VERSION ""

NS_ :

BS_ :

BU_ : ADAS BDY CAM EBCM EON EPS PCM SCM VSA XXX

BO_ 57 UNKNOWN_039: 2 XXX

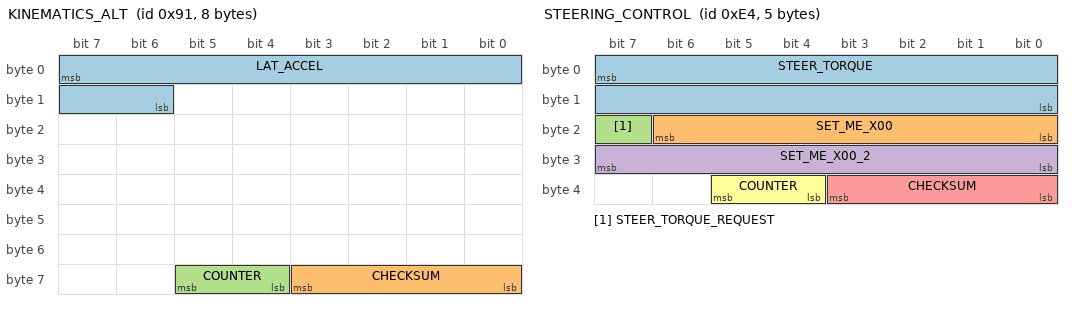
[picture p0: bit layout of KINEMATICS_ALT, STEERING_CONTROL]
BO_ 145 KINEMATICS_ALT: 8 XXX
 SG_ LAT_ACCEL : 7|10@0+ (0.02,-512) [-20|20] "m/s2" EON
 SG_ CHECKSUM : 59|4@0+ (1,0) [0|3] "" EON
 SG_ COUNTER : 61|2@0+ (1,0) [0|3] "" EON

BO_ 228 STEERING_CONTROL: 5 ADAS
 SG_ STEER_TORQUE : 7|16@0- (1,0) [-3840|3840] "" EPS
 SG_ SET_ME_X00 : 22|7@0+ (1,0) [0|127] "" EPS
 SG_ STEER_TORQUE_REQUEST : 23|1@0+ (1,0) [0|1] "" EPS
 SG_ SET_ME_X00_2 : 31|8@0+ (1,0) [0|0] "" EPS
 SG_ CHECKSUM : 35|4@0+ (1,0) [0|15] "" EPS
 SG_ COUNTER : 37|2@0+ (1,0) [0|3] "" EPS

BO_ 310 NEW_MSG_136: 8 XXX

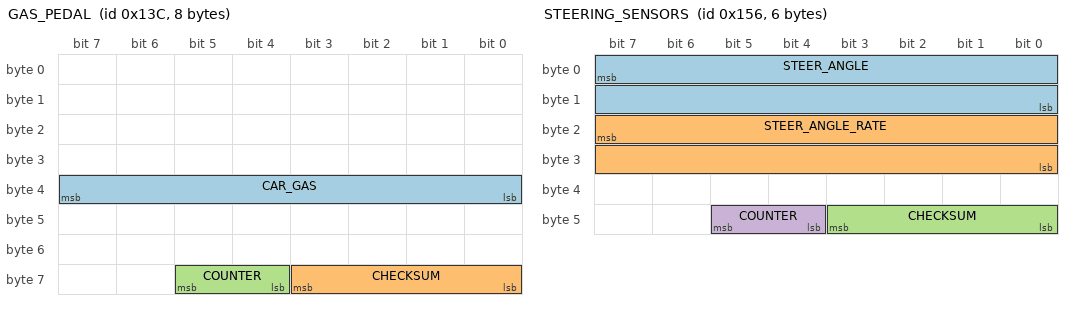
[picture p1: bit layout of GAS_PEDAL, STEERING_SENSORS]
BO_ 316 GAS_PEDAL: 8 PCM
 SG_ CAR_GAS : 39|8@0+ (1,0) [0|255] "" EON
 SG_ CHECKSUM : 59|4@0+ (1,0) [0|15] "" EON
 SG_ COUNTER : 61|2@0+ (1,0) [0|3] "" EON

BO_ 342 STEERING_SENSORS: 6 EPS
 SG_ STEER_ANGLE : 7|16@0- (-0.1,0) [-500|500] "deg" EON
 SG_ STEER_ANGLE_RATE : 23|16@0- (1,0) [-3000|3000] "deg/s" EON
 SG_ CHECKSUM : 43|4@0+ (1,0) [0|15] "" EON
 SG_ COUNTER : 45|2@0+ (1,0) [0|3] "" EON

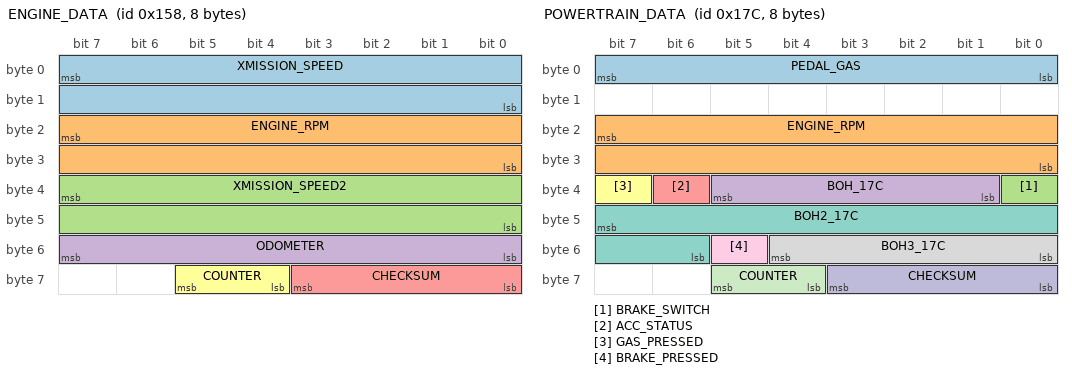
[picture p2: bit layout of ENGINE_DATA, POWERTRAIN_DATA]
BO_ 344 ENGINE_DATA: 8 PCM
 SG_ XMISSION_SPEED : 7|16@0+ (0.01,0) [0|250] "kph" EON
 SG_ ENGINE_RPM : 23|16@0+ (1,0) [0|15000] "rpm" EON
 SG_ XMISSION_SPEED2 : 39|16@0+ (0.01,0) [0|250] "kph" EON
 SG_ ODOMETER : 55|8@0+ (10,0) [0|2550] "m" XXX
 SG_ CHECKSUM : 59|4@0+ (1,0) [0|15] "" EON
 SG_ COUNTER : 61|2@0+ (1,0) [0|3] "" EON

BO_ 380 POWERTRAIN_DATA: 8 PCM
 SG_ PEDAL_GAS : 7|8@0+ (1,0) [0|255] "" EON
 SG_ ENGINE_RPM : 23|16@0+ (1,0) [0|15000] "rpm" EON
 SG_ BRAKE_SWITCH : 32|1@0+ (1,0) [0|1] "" EON
 SG_ BOH_17C : 37|5@0+ (1,0) [0|1] "" EON
 SG_ ACC_STATUS : 38|1@0+ (1,0) [0|1] "" EON
 SG_ GAS_PRESSED : 39|1@0+ (1,0) [0|1] "" EON
 SG_ BOH2_17C : 47|10@0+ (1,0) [0|1] "" EON
 SG_ BOH3_17C : 52|5@0+ (1,0) [0|1] "" EON
 SG_ BRAKE_PRESSED : 53|1@0+ (1,0) [0|1] "" EON
 SG_ CHECKSUM : 59|4@0+ (1,0) [0|15] "" EON
 SG_ COUNTER : 61|2@0+ (1,0) [0|3] "" EON

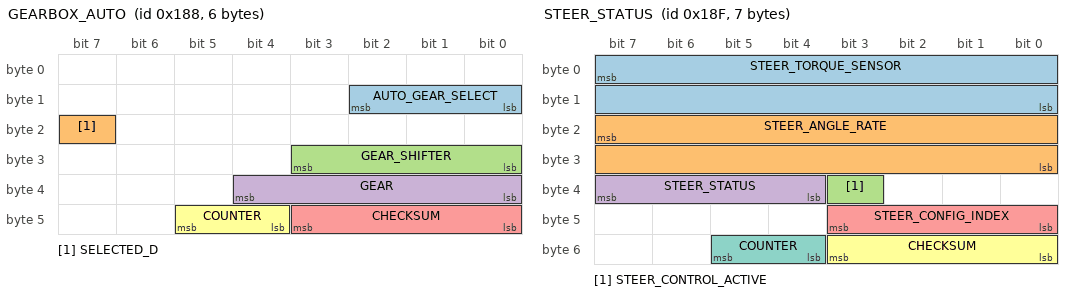
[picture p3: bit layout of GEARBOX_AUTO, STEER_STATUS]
BO_ 392 GEARBOX_AUTO: 6 XXX
 SG_ AUTO_GEAR_SELECT : 10|3@0+ (1,0) [0|7] "" XXX
 SG_ SELECTED_D : 23|1@0+ (1,0) [0|1] "" XXX
 SG_ GEAR_SHIFTER : 27|4@0+ (1,0) [0|15] "" EON
 SG_ GEAR : 36|5@0+ (1,0) [0|31] "" EON
 SG_ CHECKSUM : 43|4@0+ (1,0) [0|15] "" XXX
 SG_ COUNTER : 45|2@0+ (1,0) [0|3] "" XXX

BO_ 398 UNKNOWN_18E: 3 XXX

BO_ 399 STEER_STATUS: 7 EPS
 SG_ STEER_TORQUE_SENSOR : 7|16@0- (-1,0) [-31000|31000] "tbd" EON
 SG_ STEER_ANGLE_RATE : 23|16@0- (-0.1,0) [-31000|31000] "deg/s" EON
 SG_ STEER_CONTROL_ACTIVE : 35|1@0+ (1,0) [0|1] "" EON
 SG_ STEER_STATUS : 39|4@0+ (1,0) [0|15] "" EON
 SG_ STEER_CONFIG_INDEX : 43|4@0+ (1,0) [0|15] "" EON
 SG_ CHECKSUM : 51|4@0+ (1,0) [0|3] "" EON
 SG_ COUNTER : 53|2@0+ (1,0) [0|3] "" EON

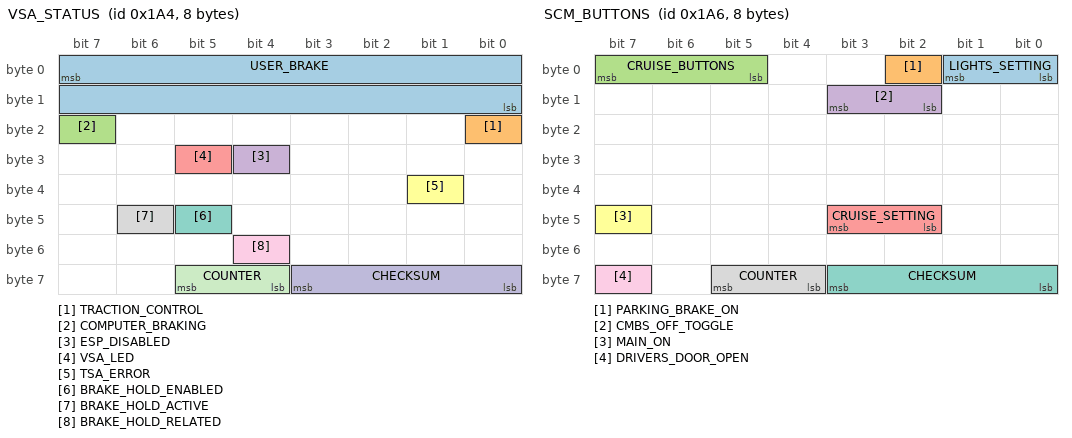
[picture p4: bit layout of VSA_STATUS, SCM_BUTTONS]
BO_ 420 VSA_STATUS: 8 VSA
 SG_ USER_BRAKE : 7|16@0+ (0.015625,-1.609375) [0|1000] "" EON
 SG_ TRACTION_CONTROL : 16|1@0+ (1,0) [0|1] "" XXX
 SG_ COMPUTER_BRAKING : 23|1@0+ (1,0) [0|1] "" EON
 SG_ ESP_DISABLED : 28|1@0+ (1,0) [0|1] "" EON
 SG_ VSA_LED : 29|1@0+ (1,0) [0|1] "" XXX
 SG_ TSA_ERROR : 33|1@0+ (1,0) [0|1] "" XXX
 SG_ BRAKE_HOLD_ENABLED : 45|1@0+ (1,0) [0|1] "" EON
 SG_ BRAKE_HOLD_ACTIVE : 46|1@0+ (1,0) [0|1] "" EON
 SG_ BRAKE_HOLD_RELATED : 52|1@0+ (1,0) [0|1] "" XXX
 SG_ CHECKSUM : 59|4@0+ (1,0) [0|15] "" EON
 SG_ COUNTER : 61|2@0+ (1,0) [0|3] "" EON

BO_ 422 SCM_BUTTONS: 8 SCM
 SG_ LIGHTS_SETTING : 1|2@0+ (1,0) [0|3] "" EON
 SG_ PARKING_BRAKE_ON : 2|1@0+ (1,0) [0|1] "" EON
 SG_ CRUISE_BUTTONS : 7|3@0+ (1,0) [0|7] "" EON
 SG_ CMBS_OFF_TOGGLE : 11|2@0+ (1,0) [0|3] "" EON
 SG_ CRUISE_SETTING : 43|2@0+ (1,0) [0|3] "" EON
 SG_ MAIN_ON : 47|1@0+ (1,0) [0|1] "" EON
 SG_ CHECKSUM : 59|4@0+ (1,0) [0|15] "" EON
 SG_ COUNTER : 61|2@0+ (1,0) [0|3] "" EON
 SG_ DRIVERS_DOOR_OPEN : 63|1@0+ (1,0) [0|1] "" EON

BO_ 426 UNKNOWN_1AA: 8 XXX

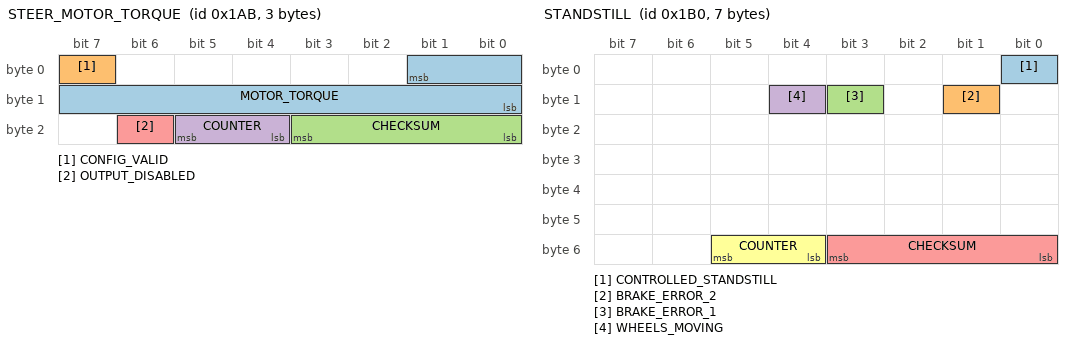
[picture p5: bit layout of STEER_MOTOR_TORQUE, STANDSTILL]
BO_ 427 STEER_MOTOR_TORQUE: 3 EPS
 SG_ MOTOR_TORQUE : 1|10@0+ (1,0) [0|256] "" EON
 SG_ CONFIG_VALID : 7|1@0+ (1,0) [0|1] "" EON
 SG_ CHECKSUM : 19|4@0+ (1,0) [0|15] "" EON
 SG_ COUNTER : 21|2@0+ (1,0) [0|3] "" EON
 SG_ OUTPUT_DISABLED : 22|1@0+ (1,0) [0|1] "" EON

BO_ 432 STANDSTILL: 7 VSA
 SG_ CONTROLLED_STANDSTILL : 0|1@0+ (1,0) [0|1] "" EON
 SG_ BRAKE_ERROR_2 : 9|1@0+ (1,0) [0|1] "" EON
 SG_ BRAKE_ERROR_1 : 11|1@0+ (1,0) [0|1] "" EON
 SG_ WHEELS_MOVING : 12|1@0+ (1,0) [0|1] "" EON
 SG_ CHECKSUM : 51|4@0+ (1,0) [0|3] "" EON
 SG_ COUNTER : 53|2@0+ (1,0) [0|3] "" EON

BO_ 448 BRAKE_COMMAND: 7 XXX
 SG_ COMPUTER_BRAKE : 7|10@0+ (1,0) [0|1] "" EBCM
 SG_ BRAKE_PUMP_REQUEST : 8|1@0+ (1,0) [0|1] "" EBCM
 SG_ BRAKE_PUMP_REQUEST_HYBRID : 11|1@0+ (1,0) [0|1] "" EBCM
 SG_ CMBS_DISABLED : 12|1@0+ (1,0) [0|1] "" XXX
 SG_ COMPUTER_BRAKE_REQUEST : 16|1@0+ (1,0) [0|1] "" EBCM
 SG_ CRUISE_CANCEL_CMD : 17|1@0+ (1,0) [0|1] "" EBCM
 SG_ CRUISE_FAULT_CMD : 18|1@0+ (1,0) [0|1] "" EBCM
 SG_ SET_ME_X00_2 : 19|1@0+ (1,0) [0|1] "" EBCM
 SG_ CRUISE_OVERRIDE : 20|1@0+ (1,0) [0|1] "" EBCM
 SG_ ACC_OVERRIDE_STOP : 21|1@0+ (1,0) [0|1] "" EBCM
 SG_ SET_ME_0 : 22|1@0+ (1,0) [0|1] "" EBCM
 SG_ ACC_LAST_BIT : 23|1@0+ (1,0) [0|1] "" EBCM
 SG_ AEB_REQ_2 : 26|3@0+ (1,0) [0|7] "" XXX
 SG_ AEB_REQ_1 : 29|2@0+ (1,0) [0|1] "" XXX
 SG_ IMPERIAL_UNIT : 31|1@0+ (1,0) [0|1] "" EBCM
 SG_ CRUISE_STATES : 38|7@0+ (1,0) [0|1] "" EBCM
 SG_ BRAKE_LIGHTS : 39|1@0+ (1,0) [0|1] "" EBCM
 SG_ AEB_STATUS : 41|2@0+ (1,0) [0|3] "" XXX
 SG_ FCW : 43|2@0+ (1,0) [0|3] "" EBCM
 SG_ SET_ME_X00_3 : 44|1@0+ (1,0) [0|1] "" EBCM
 SG_ CHIME : 47|3@0+ (1,0) [0|7] "" EBCM
 SG_ CHECKSUM : 51|4@0+ (1,0) [0|15] "" EBCM
 SG_ COUNTER : 53|2@0+ (1,0) [0|3] "" EBCM

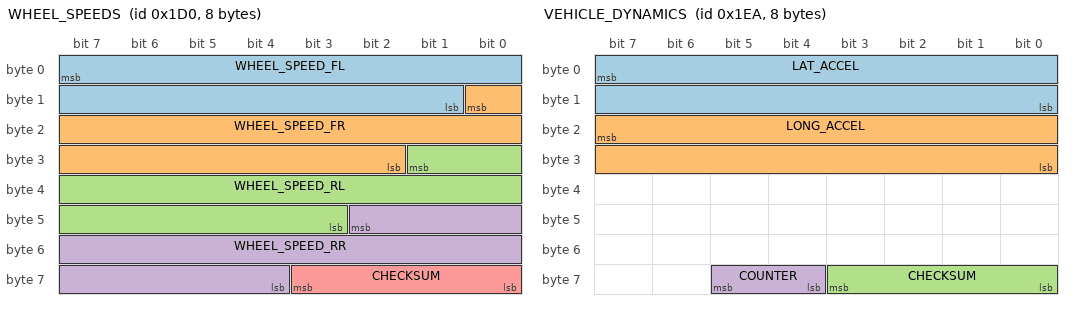
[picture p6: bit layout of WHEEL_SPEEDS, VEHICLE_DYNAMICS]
BO_ 464 WHEEL_SPEEDS: 8 VSA
 SG_ WHEEL_SPEED_FL : 7|15@0+ (0.01,0) [0|250] "kph" EON
 SG_ WHEEL_SPEED_FR : 8|15@0+ (0.01,0) [0|250] "kph" EON
 SG_ WHEEL_SPEED_RL : 25|15@0+ (0.01,0) [0|250] "kph" EON
 SG_ WHEEL_SPEED_RR : 42|15@0+ (0.01,0) [0|250] "kph" EON
 SG_ CHECKSUM : 59|4@0+ (1,0) [0|3] "" EON

BO_ 476 UNKNOWN_1DC: 4 XXX

BO_ 490 VEHICLE_DYNAMICS: 8 VSA
 SG_ LAT_ACCEL : 7|16@0- (0.0015,0) [-20|20] "m/s2" EON
 SG_ LONG_ACCEL : 23|16@0- (0.0015,0) [-20|20] "m/s2" EON
 SG_ CHECKSUM : 59|4@0+ (1,0) [0|3] "" EON
 SG_ COUNTER : 61|2@0+ (1,0) [0|3] "" EON

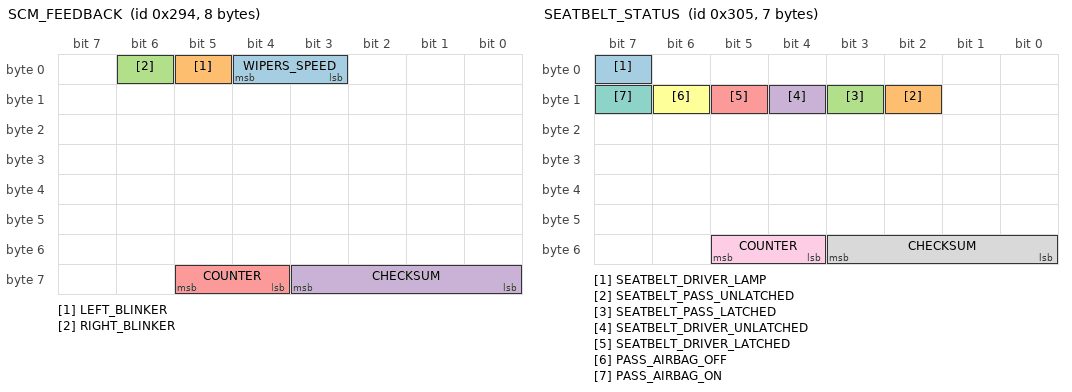
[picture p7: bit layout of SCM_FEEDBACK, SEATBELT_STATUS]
BO_ 660 SCM_FEEDBACK: 8 SCM
 SG_ WIPERS_SPEED : 4|2@0+ (1,0) [0|3] "" EON
 SG_ LEFT_BLINKER : 5|1@0+ (1,0) [0|1] "" EON
 SG_ RIGHT_BLINKER : 6|1@0+ (1,0) [0|1] "" EON
 SG_ CHECKSUM : 59|4@0+ (1,0) [0|15] "" EON
 SG_ COUNTER : 61|2@0+ (1,0) [0|3] "" EON

BO_ 773 SEATBELT_STATUS: 7 BDY
 SG_ SEATBELT_DRIVER_LAMP : 7|1@0+ (1,0) [0|1] "" EON
 SG_ SEATBELT_PASS_UNLATCHED : 10|1@0+ (1,0) [0|1] "" EON
 SG_ SEATBELT_PASS_LATCHED : 11|1@0+ (1,0) [0|1] "" EON
 SG_ SEATBELT_DRIVER_UNLATCHED : 12|1@0+ (1,0) [0|1] "" EON
 SG_ SEATBELT_DRIVER_LATCHED : 13|1@0+ (1,0) [0|1] "" EON
 SG_ PASS_AIRBAG_OFF : 14|1@0+ (1,0) [0|1] "" EON
 SG_ PASS_AIRBAG_ON : 15|1@0+ (1,0) [0|1] "" EON
 SG_ CHECKSUM : 51|4@0+ (1,0) [0|3] "" EON
 SG_ COUNTER : 53|2@0+ (1,0) [0|3] "" EON

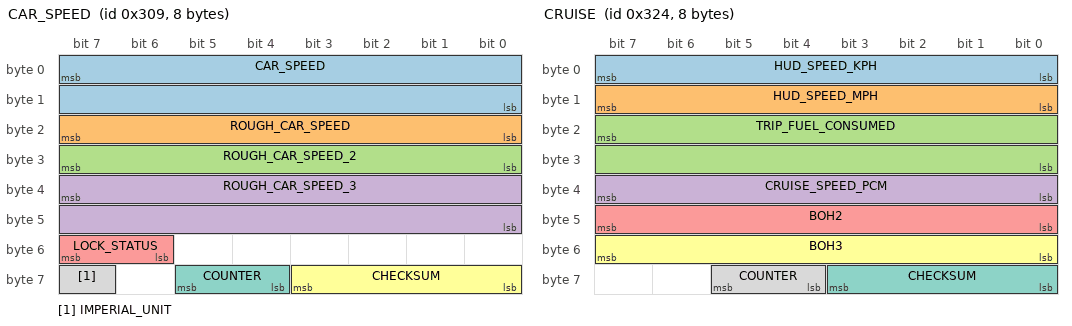
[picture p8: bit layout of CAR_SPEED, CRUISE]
BO_ 777 CAR_SPEED: 8 PCM
 SG_ CAR_SPEED : 7|16@0+ (0.01,0) [0|65535] "kph" XXX
 SG_ ROUGH_CAR_SPEED : 23|8@0+ (1,0) [0|255] "mph" XXX
 SG_ ROUGH_CAR_SPEED_2 : 31|8@0+ (1,0) [0|255] "mph" XXX
 SG_ ROUGH_CAR_SPEED_3 : 39|16@0+ (1,0) [0|65535] "kph" XXX
 SG_ LOCK_STATUS : 55|2@0+ (1,0) [0|255] "" XXX
 SG_ CHECKSUM : 59|4@0+ (1,0) [0|15] "" XXX
 SG_ COUNTER : 61|2@0+ (1,0) [0|3] "" XXX
 SG_ IMPERIAL_UNIT : 63|1@0+ (1,0) [0|1] "" XXX

BO_ 780 ACC_HUD: 8 ADAS
 SG_ PCM_SPEED : 7|16@0+ (0.01,0) [0|655.35] "kph" BDY
 SG_ PCM_GAS : 23|8@0+ (1,0) [0|255] "" BDY
 SG_ CRUISE_SPEED : 31|8@0+ (1,0) [0|255] "kph" BDY
 SG_ ENABLE_MINI_CAR : 32|1@0+ (1,0) [0|1] "" BDY
 SG_ RADAR_OBSTRUCTED : 33|1@0+ (1,0) [0|1] "" BDY
 SG_ FCM_PROBLEM : 34|1@0+ (1,0) [0|1] "" BDY
 SG_ FCM_OFF : 35|1@0+ (1,0) [0|1] "" BDY
 SG_ FCM_OFF_2 : 36|1@0+ (1,0) [0|1] "" BDY
 SG_ ACC_PROBLEM : 37|1@0+ (1,0) [0|1] "" BDY
 SG_ BRAKE_SYSTEM_ICON : 38|1@0+ (1,0) [0|1] "" BDY
 SG_ DTC_MODE : 39|1@0+ (1,0) [0|1] "" BDY
 SG_ CRUISE_CONTROL_LABEL : 40|1@0+ (1,0) [0|1] "" BDY
 SG_ BOH_5 : 41|1@0+ (1,0) [0|1] "" BDY
 SG_ BOH_4 : 42|1@0+ (1,0) [0|1] "" BDY
 SG_ BOH_3 : 43|1@0+ (1,0) [0|1] "" BDY
 SG_ HUD_LEAD : 45|2@0+ (1,0) [0|3] "" BDY
 SG_ HUD_DISTANCE : 47|2@0+ (1,0) [0|3] "" BDY
 SG_ ACC_HUD_STROBE : 48|1@0+ (1,0) [0|1] "" BDY
 SG_ CHIME : 51|3@0+ (1,0) [0|7] "" BDY
 SG_ ACC_ON : 52|1@0+ (1,0) [0|1] "" BDY
 SG_ IMPERIAL_UNIT : 54|1@0+ (1,0) [0|1] "" BDY
 SG_ SET_ME_X01_2 : 55|1@0+ (1,0) [0|1] "" BDY
 SG_ CHECKSUM : 59|4@0+ (1,0) [0|15] "" BDY
 SG_ COUNTER : 61|2@0+ (1,0) [0|3] "" BDY
 SG_ ICONS : 63|2@0+ (1,0) [0|3] "" BDY

BO_ 800 UNKNOWN_320: 3 XXX

BO_ 804 CRUISE: 8 PCM
 SG_ HUD_SPEED_KPH : 7|8@0+ (1,0) [0|255] "kph" EON
 SG_ HUD_SPEED_MPH : 15|8@0+ (1,0) [0|255] "mph" EON
 SG_ TRIP_FUEL_CONSUMED : 23|16@0+ (1,0) [0|255] "" EON
 SG_ CRUISE_SPEED_PCM : 39|8@0+ (1,0) [0|255] "" EON
 SG_ BOH2 : 47|8@0- (1,0) [0|255] "" EON
 SG_ BOH3 : 55|8@0+ (1,0) [0|255] "" EON
 SG_ CHECKSUM : 59|4@0+ (1,0) [0|15] "" EON
 SG_ COUNTER : 61|2@0+ (1,0) [0|3] "" EON

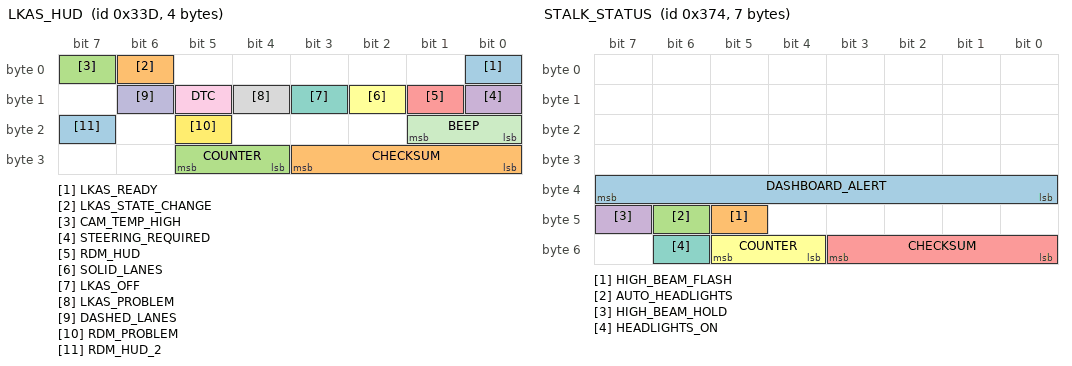
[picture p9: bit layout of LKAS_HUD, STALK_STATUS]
BO_ 829 LKAS_HUD: 4 ADAS
 SG_ LKAS_READY : 0|1@0+ (1,0) [0|127] "" BDY
 SG_ LKAS_STATE_CHANGE : 6|1@0+ (1,0) [0|1] "" XXX
 SG_ CAM_TEMP_HIGH : 7|1@0+ (1,0) [0|255] "" BDY
 SG_ STEERING_REQUIRED : 8|1@0+ (1,0) [0|1] "" BDY
 SG_ RDM_HUD : 9|1@0+ (1,0) [0|1] "" BDY
 SG_ SOLID_LANES : 10|1@0+ (1,0) [0|1] "" BDY
 SG_ LKAS_OFF : 11|1@0+ (1,0) [0|1] "" BDY
 SG_ LKAS_PROBLEM : 12|1@0+ (1,0) [0|1] "" BDY
 SG_ DTC : 13|1@0+ (1,0) [0|1] "" BDY
 SG_ DASHED_LANES : 14|1@0+ (1,0) [0|1] "" BDY
 SG_ BEEP : 17|2@0+ (1,0) [0|1] "" BDY
 SG_ RDM_PROBLEM : 21|1@0+ (1,0) [0|1] "" BDY
 SG_ RDM_HUD_2 : 23|1@0+ (1,0) [0|1] "" XXX
 SG_ CHECKSUM : 27|4@0+ (1,0) [0|15] "" BDY
 SG_ COUNTER : 29|2@0+ (1,0) [0|3] "" BDY

BO_ 884 STALK_STATUS: 7 XXX
 SG_ DASHBOARD_ALERT : 39|8@0+ (1,0) [0|255] "" EON
 SG_ HIGH_BEAM_FLASH : 45|1@0+ (1,0) [0|1] "" EON
 SG_ AUTO_HEADLIGHTS : 46|1@0+ (1,0) [0|1] "" EON
 SG_ HIGH_BEAM_HOLD : 47|1@0+ (1,0) [0|1] "" EON
 SG_ CHECKSUM : 51|4@0+ (1,0) [0|3] "" EON
 SG_ COUNTER : 53|2@0+ (1,0) [0|3] "" EON
 SG_ HEADLIGHTS_ON : 54|1@0+ (1,0) [0|1] "" EON

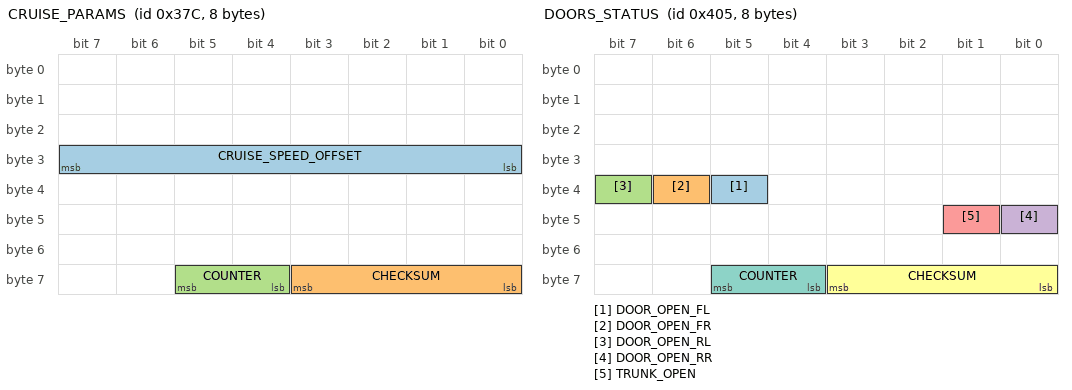
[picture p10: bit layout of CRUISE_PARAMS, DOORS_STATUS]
BO_ 892 CRUISE_PARAMS: 8 PCM
 SG_ CRUISE_SPEED_OFFSET : 31|8@0- (0.1,0) [-128|127] "kph" EON
 SG_ CHECKSUM : 59|4@0+ (1,0) [0|3] "" EON
 SG_ COUNTER : 61|2@0+ (1,0) [0|3] "" EON

BO_ 983 UNKNOWN_3D7: 8 XXX

BO_ 1024 UNKNOWN_400: 5 XXX

BO_ 1029 DOORS_STATUS: 8 BDY
 SG_ DOOR_OPEN_FL : 37|1@0+ (1,0) [0|1] "" EON
 SG_ DOOR_OPEN_FR : 38|1@0+ (1,0) [0|1] "" EON
 SG_ DOOR_OPEN_RL : 39|1@0+ (1,0) [0|1] "" EON
 SG_ DOOR_OPEN_RR : 40|1@0+ (1,0) [0|1] "" EON
 SG_ TRUNK_OPEN : 41|1@0+ (1,0) [0|1] "" EON
 SG_ CHECKSUM : 59|4@0+ (1,0) [0|15] "" EON
 SG_ COUNTER : 61|2@0+ (1,0) [0|3] "" EON

BO_ 1030 UNKNOWN_406: 5 XXX

BO_ 1036 UNKNOWN_40C: 8 XXX

BO_ 1064 UNKNOWN_428: 7 XXX

BO_ 1108 UNKNOWN_454: 6 XXX

BO_ 1125 UNKNOWN_465: 7 XXX

CM_ BO_ 57 "GUESS/unidentified: dlc 3 varying bytes [1, 2]; likely body/comfort/diagnostic.";
CM_ BO_ 228 "v3 note: OP steering TX (not on sampled non-lateral drives)";
CM_ SG_ 316 CAR_GAS "Should exist on Nidec";
CM_ BO_ 398 "GUESS/unidentified: dlc 3 varying bytes [1, 2]; likely body/comfort/diagnostic.";
CM_ SG_ 420 BRAKE_HOLD_RELATED "On when Brake Hold engaged";
CM_ BO_ 426 "GUESS/unidentified: dlc 8 varying bytes [3, 7]; likely body/comfort/diagnostic.";
CM_ BO_ 427 "v3 note: not seen on sample, verify";
CM_ BO_ 476 "GUESS: best match vEgo_kph corr 0.58; scale is a fit, verify.";
CM_ SG_ 490 LONG_ACCEL "wheel speed derivative, noisy and zero snapping";
CM_ SG_ 773 PASS_AIRBAG_OFF "Might just be indicator light";
CM_ SG_ 773 PASS_AIRBAG_ON "Might just be indicator light";
CM_ BO_ 780 "ACC_HUD, 10Hz, from radar/ACC unit. Same Honda checksum/counter as 506 (verified 100.0000% on 64880 stock frames). Stock never sets ACC_PROBLEM/FCM_*; those appear only when openpilot is active (7.2% duty on 84-8b).";
CM_ SG_ 780 PCM_SPEED "ACC target speed, 0.01 kph. =0 at standstill (84% of zero-speed frames). v3 max [0|250] was wrong (16-bit*0.01 -> 655.35).";
CM_ SG_ 780 PCM_GAS "ACC powertrain gas/torque request. Dominant idle value ~198; varies with ACC accel demand. v3 max [0|127] wrong (8-bit -> 255).";
CM_ SG_ 780 CRUISE_SPEED "Set speed in kph; 255 = no set speed (ACC not engaged). 255 in 53% of stock frames.";
CM_ SG_ 780 ENABLE_MINI_CAR "= ACC engaged. P(set|cruiseState.enabled)=1.00, P(set|!enabled)=0.001. Shows host car on HUD.";
CM_ SG_ 780 RADAR_OBSTRUCTED "0 in stock.";
CM_ SG_ 780 FCM_PROBLEM "Forward Camera/Radar Module problem. Tracks ACC_PROBLEM. 0 in stock, 7.2% when OP active.";
CM_ SG_ 780 FCM_OFF "0 in stock.";
CM_ SG_ 780 FCM_OFF_2 "0 in stock.";
CM_ SG_ 780 ACC_PROBLEM "ACC fault annunciation. Stock 81/82: 0. OP-active 84-8b: 1 in 7.21% (3507 onsets). Equals FCM_PROBLEM (99.996%). Primary bit behind the dash ACC error.";
CM_ SG_ 780 BRAKE_SYSTEM_ICON "Rare (106/64880); pairs with ICONS=3.";
CM_ SG_ 780 CRUISE_CONTROL_LABEL "0 in stock (1-bit; v3 max [0|3] corrected to [0|1]).";
CM_ SG_ 780 BOH_5 "0 in stock.";
CM_ SG_ 780 BOH_3 "0 in stock.";
CM_ SG_ 780 HUD_LEAD "0=ACC off / no host car; 1=engaged, no lead; 2=engaged, lead shown; 3=lead while disengaged (warning). Joint with ENABLE_MINI_CAR: =0 when mini_car=0, =1/2 split by lead presence (96.6-96.7%).";
CM_ SG_ 780 HUD_DISTANCE "Driver-selected follow-gap setting. Static (changes 0.002% of frames); NOT a live distance. Observed 1-2; field supports 0-3.";
CM_ SG_ 780 ACC_HUD_STROBE "v4 rename of v3 SET_ME_X01 (bit48). NOT a constant: pulses at ACC engage/disengage transitions. P(set|ACC_ON just changed)=0.80 vs 0.055 baseline; ENABLE_MINI_CAR=1 in 97%.";
CM_ SG_ 780 ACC_ON "ACC actively engaged/controlling (engaged 99.9% when 1). Radar's own engaged truth.";
CM_ SG_ 780 IMPERIAL_UNIT "0 across stock frames on this car.";
CM_ SG_ 780 SET_ME_X01_2 "Reserved CONSTANT = 1 across all 64880 stock frames. openpilot MUST send 1.";
CM_ BO_ 800 "GUESS/unidentified: dlc 8 varying bytes [7]; likely body/comfort/diagnostic.";
CM_ SG_ 804 CRUISE_SPEED_PCM "255 = no speed";
CM_ SG_ 829 CAM_TEMP_HIGH "Some Driver Assist Systems Cannot Operate: Camera Temperature Too High";
CM_ SG_ 829 BEEP "beeps are pleasant, chimes are for warnings etc...";
CM_ BO_ 983 "GUESS/unidentified: dlc 8 varying bytes [7]; likely body/comfort/diagnostic.";
CM_ BO_ 1024 "GUESS/unidentified: dlc 5 varying bytes [2, 4]; likely body/comfort/diagnostic.";
CM_ BO_ 1030 "GUESS/unidentified: dlc 5 varying bytes [3, 4]; likely body/comfort/diagnostic.";
CM_ BO_ 1036 "GUESS/unidentified: dlc 8 varying bytes [0, 1, 2, 3, 4, 5, 6, 7]; likely body/comfort/diagnostic.";
CM_ BO_ 1064 "GUESS/unidentified: dlc 7 varying bytes [6]; likely body/comfort/diagnostic.";
CM_ BO_ 1108 "GUESS/unidentified: dlc 8 varying bytes [6, 7]; likely body/comfort/diagnostic.";
CM_ BO_ 1125 "GUESS: best match vEgo_kph corr 0.66; scale is a fit, verify.";
VAL_ 392 AUTO_GEAR_SELECT 7 "6" 6 "R" 0 "P";
VAL_ 392 GEAR_SHIFTER 0 "S" 1 "P" 2 "R" 4 "N" 8 "D";
VAL_ 392 GEAR 26 "S" 4 "D" 3 "N" 2 "R" 1 "P";
VAL_ 399 STEER_STATUS 7 "permanent_fault" 6 "tmp_fault" 5 "fault_1" 4 "no_torque_alert_2" 3 "low_speed_lockout" 2 "no_torque_alert_1" 1 "driver_steering" 0 "normal";
VAL_ 422 LIGHTS_SETTING 3 "high_beam" 2 "low_beam" 1 "position" 0 "no_lights";
VAL_ 422 CRUISE_BUTTONS 7 "tbd" 6 "tbd" 5 "tbd" 4 "accel_res" 3 "decel_set" 2 "cancel" 1 "main" 0 "none";
VAL_ 422 CRUISE_SETTING 3 "distance_adj" 2 "tbd" 1 "lkas_button" 0 "none";
VAL_ 780 CRUISE_SPEED 255 "no_speed" 252 "stopped";
VAL_ 780 HUD_LEAD 3 "lead_disengaged_warn" 2 "engaged_lead" 1 "engaged_no_lead" 0 "off_no_car";
VAL_ 780 ACC_ON 1 "acc_engaged" 0 "off";
VAL_ 829 BEEP 5 "solid_beep" 4 "double_beep" 3 "single_beep" 2 "triple_beep" 1 "repeated_beep" 0 "no_beep";
VAL_ 884 DASHBOARD_ALERT 0 "none" 51 "acc_problem" 55 "cmbs_problem" 75 "key_not_detected" 79 "fasten_seatbelt" 111 "lkas_problem" 131 "brake_system_problem" 132 "brake_hold_problem" 139 "tbd" 161 "door_open";
